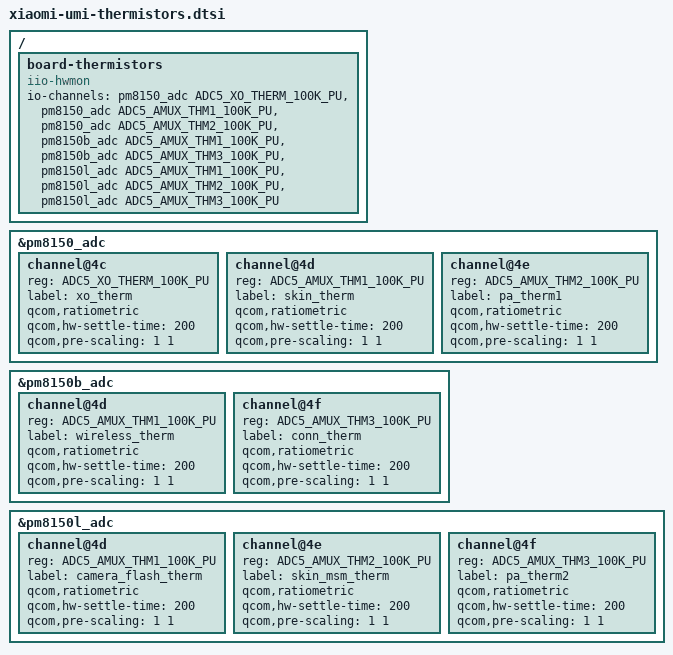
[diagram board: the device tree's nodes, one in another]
// SPDX-License-Identifier: BSD-3-Clause
/* Xiaomi umi board thermistors, using the upstream PMIC ADC5 driver.
 * Source: MiCode/kernel_devicetree umi-q-oss,
 * 2aa073826fa357cc672c1e0f590d9dbe904203b0, qcom/umi-sm8250.dtsi.
 * Downstream ADC_*_PU2 IDs 0x4c..0x4f map to ADC5_*_100K_PU.
 * Preserve its ratiometric calibration, 1:1 prescaling and 200 us settling.
 * This exposes measurements, not a charging or thermal protection policy.
 * The vendor user-space thermal zones use 125 C trips; those
 * must not become mainline protection thresholds without board validation.
 */

#include <dt-bindings/iio/qcom,spmi-vadc.h>

/ {
	board-thermistors {
		compatible = "iio-hwmon";
		io-channels = <&pm8150_adc ADC5_XO_THERM_100K_PU>,
			      <&pm8150_adc ADC5_AMUX_THM1_100K_PU>,
			      <&pm8150_adc ADC5_AMUX_THM2_100K_PU>,
			      <&pm8150b_adc ADC5_AMUX_THM1_100K_PU>,
			      <&pm8150b_adc ADC5_AMUX_THM3_100K_PU>,
			      <&pm8150l_adc ADC5_AMUX_THM1_100K_PU>,
			      <&pm8150l_adc ADC5_AMUX_THM2_100K_PU>,
			      <&pm8150l_adc ADC5_AMUX_THM3_100K_PU>;
	};
};

&pm8150_adc {
	channel@4c {
		reg = <ADC5_XO_THERM_100K_PU>;
		label = "xo_therm";
		qcom,ratiometric;
		qcom,hw-settle-time = <200>;
		qcom,pre-scaling = <1 1>;
	};

	channel@4d {
		reg = <ADC5_AMUX_THM1_100K_PU>;
		label = "skin_therm";
		qcom,ratiometric;
		qcom,hw-settle-time = <200>;
		qcom,pre-scaling = <1 1>;
	};

	channel@4e {
		reg = <ADC5_AMUX_THM2_100K_PU>;
		label = "pa_therm1";
		qcom,ratiometric;
		qcom,hw-settle-time = <200>;
		qcom,pre-scaling = <1 1>;
	};
};

&pm8150b_adc {
	channel@4d {
		reg = <ADC5_AMUX_THM1_100K_PU>;
		label = "wireless_therm";
		qcom,ratiometric;
		qcom,hw-settle-time = <200>;
		qcom,pre-scaling = <1 1>;
	};

	channel@4f {
		reg = <ADC5_AMUX_THM3_100K_PU>;
		label = "conn_therm";
		qcom,ratiometric;
		qcom,hw-settle-time = <200>;
		qcom,pre-scaling = <1 1>;
	};
};

&pm8150l_adc {
	channel@4d {
		reg = <ADC5_AMUX_THM1_100K_PU>;
		label = "camera_flash_therm";
		qcom,ratiometric;
		qcom,hw-settle-time = <200>;
		qcom,pre-scaling = <1 1>;
	};

	channel@4e {
		reg = <ADC5_AMUX_THM2_100K_PU>;
		label = "skin_msm_therm";
		qcom,ratiometric;
		qcom,hw-settle-time = <200>;
		qcom,pre-scaling = <1 1>;
	};

	channel@4f {
		reg = <ADC5_AMUX_THM3_100K_PU>;
		label = "pa_therm2";
		qcom,ratiometric;
		qcom,hw-settle-time = <200>;
		qcom,pre-scaling = <1 1>;
	};
};
